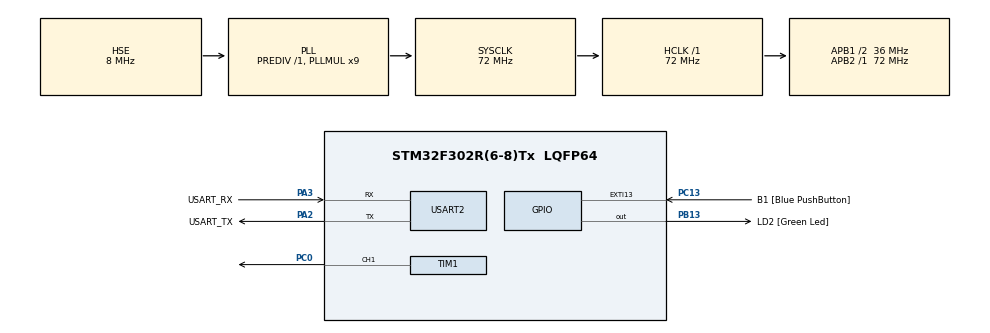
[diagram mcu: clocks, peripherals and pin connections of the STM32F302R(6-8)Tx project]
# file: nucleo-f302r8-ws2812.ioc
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Dma.Request0=TIM1_CH1
Dma.TIM1_CH1.0.Direction=DMA_MEMORY_TO_PERIPH
Dma.TIM1_CH1.0.Instance=DMA1_Channel2
Dma.TIM1_CH1.0.MemDataAlignment=DMA_MDATAALIGN_BYTE
Dma.TIM1_CH1.0.MemInc=DMA_MINC_ENABLE
Dma.TIM1_CH1.0.Mode=DMA_NORMAL
Dma.TIM1_CH1.0.PeriphDataAlignment=DMA_PDATAALIGN_HALFWORD
Dma.TIM1_CH1.0.PeriphInc=DMA_PINC_DISABLE
Dma.TIM1_CH1.0.Priority=DMA_PRIORITY_LOW
Mcu.Family=STM32F3
Mcu.Name=STM32F302R(6-8)Tx
Mcu.Package=LQFP64
NVIC.DMA1_Channel2_IRQn=true\:0\:0\:false\:false\:true\:false\:true\:true
NVIC.PriorityGroup=NVIC_PRIORITYGROUP_0
PA13.GPIO_Label=TMS
PA13.Mode=Serial_Wire
PA13.Signal=SYS_JTMS-SWDIO
PA14.GPIO_Label=TCK
PA14.Mode=Serial_Wire
PA14.Signal=SYS_JTCK-SWCLK
PA2.GPIO_Label=USART_TX
PA2.GPIO_Mode=GPIO_MODE_AF_PP
PA2.GPIO_PuPd=GPIO_NOPULL
PA2.GPIO_Speed=GPIO_SPEED_FREQ_LOW
PA2.Mode=Asynchronous
PA2.Signal=USART2_TX
PA3.GPIO_Label=USART_RX
PA3.GPIO_Mode=GPIO_MODE_AF_PP
PA3.GPIO_PuPd=GPIO_NOPULL
PA3.GPIO_Speed=GPIO_SPEED_FREQ_LOW
PA3.Mode=Asynchronous
PA3.Signal=USART2_RX
PB13.GPIO_Label=LD2 [Green Led]
PB13.Signal=GPIO_Output
PB3.GPIO_Label=SWO
PB3.Mode=Trace_Asynchronous_SW
PB3.Signal=SYS_JTDO-TRACESWO
PC0.GPIO_PuPd=GPIO_NOPULL
PC0.GPIO_Speed=GPIO_SPEED_FREQ_HIGH
PC0.Signal=S_TIM1_CH1
PC13.GPIO_Label=B1 [Blue PushButton]
PC13.GPIO_ModeDefaultEXTI=GPIO_MODE_IT_FALLING
PC13.Signal=GPXTI13
PC14\ -\ OSC32_IN.Mode=LSE-External-Oscillator
PC14\ -\ OSC32_IN.Signal=RCC_OSC32_IN
PC15\ -\ OSC32_OUT.Mode=LSE-External-Oscillator
PC15\ -\ OSC32_OUT.Signal=RCC_OSC32_OUT
PF0-OSC_IN.Mode=HSE-External-Clock-Source
PF0-OSC_IN.Signal=RCC_OSC_IN
PF1-OSC_OUT.Signal=RCC_OSC_OUT
ProjectManager.HeapSize=0x200
ProjectManager.StackSize=0x400
ProjectManager.TargetToolchain=Makefile
RCC.AHBFreq_Value=72000000
RCC.APB1CLKDivider=RCC_HCLK_DIV2
RCC.APB1Freq_Value=36000000
RCC.APB1TimFreq_Value=72000000
RCC.APB2Freq_Value=72000000
RCC.APB2TimFreq_Value=72000000
RCC.CortexFreq_Value=72000000
RCC.HCLKFreq_Value=72000000
RCC.HSE_VALUE=8000000
RCC.HSI_VALUE=8000000
RCC.PLLM=8
RCC.PLLMUL=RCC_PLL_MUL9
RCC.PLLN=336
RCC.PLLP=RCC_PLLP_DIV4
RCC.PLLQ=7
RCC.PLLSourceVirtual=RCC_PLLSOURCE_HSE
RCC.SYSCLKFreq_VALUE=72000000
RCC.SYSCLKSourceVirtual=RCC_SYSCLKSOURCE_PLLCLK
RCC.USBFreq_Value=72000000
SH.S_TIM1_CH1.0=TIM1_CH1,PWM Generation1 CH1
TIM1.AutoReloadPreload=TIM_AUTORELOAD_PRELOAD_ENABLE
TIM1.Channel-PWM\ Generation1\ CH1=TIM_CHANNEL_1
TIM1.Period=90-1
USART2.VirtualMode-Asynchronous=VM_ASYNC
VP_TIM1_VS_ClockSourceINT.Mode=Internal
board=NUCLEO-F302R8

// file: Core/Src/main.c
/* USER CODE BEGIN Header */
/**
  ******************************************************************************
  * @file           : main.c
  * @brief          : Main program body
  ******************************************************************************
  * @attention
  *
  * Copyright (c) 2024 STMicroelectronics.
  * All rights reserved.
  *
  * This software is licensed under terms that can be found in the LICENSE file
  * in the root directory of this software component.
  * If no LICENSE file comes with this software, it is provided AS-IS.
  *
  ******************************************************************************
  */
/* USER CODE END Header */
#include "main.h"

/* USER CODE BEGIN Includes */
#include "application.h"
/* USER CODE END Includes */

TIM_HandleTypeDef htim1;
DMA_HandleTypeDef hdma_tim1_ch1;

UART_HandleTypeDef huart2;

void SystemClock_Config(void);
static void MX_GPIO_Init(void);
static void MX_DMA_Init(void);
static void MX_USART2_UART_Init(void);
static void MX_TIM1_Init(void);
/* USER CODE BEGIN PFP */
void initialise_monitor_handles();
/* USER CODE END PFP */

int main(void)
{

  /* USER CODE BEGIN 1 */
  initialise_monitor_handles();
  /* USER CODE END 1 */

  /* MCU Configuration--------------------------------------------------------*/

  /* Reset of all peripherals, Initializes the Flash interface and the Systick. */
  HAL_Init();

  /* Configure the system clock */
  SystemClock_Config();

  /* Initialize all configured peripherals */
  MX_GPIO_Init();
  MX_DMA_Init();
  MX_USART2_UART_Init();
  MX_TIM1_Init();

  /* Infinite loop */
  /* USER CODE BEGIN WHILE */

  // Enable divide-by-zero trap
  SCB->CCR |= SCB_CCR_DIV_0_TRP_Msk;

  app_init();

  while (1)
  {
    /* USER CODE END WHILE */

    /* USER CODE BEGIN 3 */
    app_loop();
  }
  app_close();
  /* USER CODE END 3 */
}

void SystemClock_Config(void)
{
  RCC_OscInitTypeDef RCC_OscInitStruct = {0};
  RCC_ClkInitTypeDef RCC_ClkInitStruct = {0};
  RCC_PeriphCLKInitTypeDef PeriphClkInit = {0};

  /** Initializes the RCC Oscillators according to the specified parameters
  * in the RCC_OscInitTypeDef structure.
  */
  RCC_OscInitStruct.OscillatorType = RCC_OSCILLATORTYPE_HSE;
  RCC_OscInitStruct.HSEState = RCC_HSE_BYPASS;
  RCC_OscInitStruct.HSEPredivValue = RCC_HSE_PREDIV_DIV1;
  RCC_OscInitStruct.HSIState = RCC_HSI_ON;
  RCC_OscInitStruct.PLL.PLLState = RCC_PLL_ON;
  RCC_OscInitStruct.PLL.PLLSource = RCC_PLLSOURCE_HSE;
  RCC_OscInitStruct.PLL.PLLMUL = RCC_PLL_MUL9;
  if (HAL_RCC_OscConfig(&RCC_OscInitStruct) != HAL_OK)
  {
    Error_Handler();
  }

  /** Initializes the CPU, AHB and APB buses clocks
  */
  RCC_ClkInitStruct.ClockType = RCC_CLOCKTYPE_HCLK|RCC_CLOCKTYPE_SYSCLK
                              |RCC_CLOCKTYPE_PCLK1|RCC_CLOCKTYPE_PCLK2;
  RCC_ClkInitStruct.SYSCLKSource = RCC_SYSCLKSOURCE_PLLCLK;
  RCC_ClkInitStruct.AHBCLKDivider = RCC_SYSCLK_DIV1;
  RCC_ClkInitStruct.APB1CLKDivider = RCC_HCLK_DIV2;
  RCC_ClkInitStruct.APB2CLKDivider = RCC_HCLK_DIV1;

  if (HAL_RCC_ClockConfig(&RCC_ClkInitStruct, FLASH_LATENCY_2) != HAL_OK)
  {
    Error_Handler();
  }
  PeriphClkInit.PeriphClockSelection = RCC_PERIPHCLK_TIM1;
  PeriphClkInit.Tim1ClockSelection = RCC_TIM1CLK_HCLK;
  if (HAL_RCCEx_PeriphCLKConfig(&PeriphClkInit) != HAL_OK)
  {
    Error_Handler();
  }
}

static void MX_TIM1_Init(void)
{

  TIM_ClockConfigTypeDef sClockSourceConfig = {0};
  TIM_MasterConfigTypeDef sMasterConfig = {0};
  TIM_OC_InitTypeDef sConfigOC = {0};
  TIM_BreakDeadTimeConfigTypeDef sBreakDeadTimeConfig = {0};

  htim1.Instance = TIM1;
  htim1.Init.Prescaler = 0;
  htim1.Init.CounterMode = TIM_COUNTERMODE_UP;
  htim1.Init.Period = 90-1;
  htim1.Init.ClockDivision = TIM_CLOCKDIVISION_DIV1;
  htim1.Init.RepetitionCounter = 0;
  htim1.Init.AutoReloadPreload = TIM_AUTORELOAD_PRELOAD_ENABLE;
  if (HAL_TIM_Base_Init(&htim1) != HAL_OK)
  {
    Error_Handler();
  }
  sClockSourceConfig.ClockSource = TIM_CLOCKSOURCE_INTERNAL;
  if (HAL_TIM_ConfigClockSource(&htim1, &sClockSourceConfig) != HAL_OK)
  {
    Error_Handler();
  }
  if (HAL_TIM_PWM_Init(&htim1) != HAL_OK)
  {
    Error_Handler();
  }
  sMasterConfig.MasterOutputTrigger = TIM_TRGO_RESET;
  sMasterConfig.MasterOutputTrigger2 = TIM_TRGO2_RESET;
  sMasterConfig.MasterSlaveMode = TIM_MASTERSLAVEMODE_DISABLE;
  if (HAL_TIMEx_MasterConfigSynchronization(&htim1, &sMasterConfig) != HAL_OK)
  {
    Error_Handler();
  }
  sConfigOC.OCMode = TIM_OCMODE_PWM1;
  sConfigOC.Pulse = 0;
  sConfigOC.OCPolarity = TIM_OCPOLARITY_HIGH;
  sConfigOC.OCNPolarity = TIM_OCNPOLARITY_HIGH;
  sConfigOC.OCFastMode = TIM_OCFAST_DISABLE;
  sConfigOC.OCIdleState = TIM_OCIDLESTATE_RESET;
  sConfigOC.OCNIdleState = TIM_OCNIDLESTATE_RESET;
  if (HAL_TIM_PWM_ConfigChannel(&htim1, &sConfigOC, TIM_CHANNEL_1) != HAL_OK)
  {
    Error_Handler();
  }
  sBreakDeadTimeConfig.OffStateRunMode = TIM_OSSR_DISABLE;
  sBreakDeadTimeConfig.OffStateIDLEMode = TIM_OSSI_DISABLE;
  sBreakDeadTimeConfig.LockLevel = TIM_LOCKLEVEL_OFF;
  sBreakDeadTimeConfig.DeadTime = 0;
  sBreakDeadTimeConfig.BreakState = TIM_BREAK_DISABLE;
  sBreakDeadTimeConfig.BreakPolarity = TIM_BREAKPOLARITY_HIGH;
  sBreakDeadTimeConfig.BreakFilter = 0;
  sBreakDeadTimeConfig.Break2State = TIM_BREAK2_DISABLE;
  sBreakDeadTimeConfig.Break2Polarity = TIM_BREAK2POLARITY_HIGH;
  sBreakDeadTimeConfig.Break2Filter = 0;
  sBreakDeadTimeConfig.AutomaticOutput = TIM_AUTOMATICOUTPUT_DISABLE;
  if (HAL_TIMEx_ConfigBreakDeadTime(&htim1, &sBreakDeadTimeConfig) != HAL_OK)
  {
    Error_Handler();
  }
  HAL_TIM_MspPostInit(&htim1);

}

static void MX_USART2_UART_Init(void)
{

  huart2.Instance = USART2;
  huart2.Init.BaudRate = 38400;
  huart2.Init.WordLength = UART_WORDLENGTH_8B;
  huart2.Init.StopBits = UART_STOPBITS_1;
  huart2.Init.Parity = UART_PARITY_NONE;
  huart2.Init.Mode = UART_MODE_TX_RX;
  huart2.Init.HwFlowCtl = UART_HWCONTROL_NONE;
  huart2.Init.OverSampling = UART_OVERSAMPLING_16;
  huart2.Init.OneBitSampling = UART_ONE_BIT_SAMPLE_DISABLE;
  huart2.AdvancedInit.AdvFeatureInit = UART_ADVFEATURE_NO_INIT;
  if (HAL_UART_Init(&huart2) != HAL_OK)
  {
    Error_Handler();
  }

}

static void MX_DMA_Init(void)
{

  /* DMA controller clock enable */
  __HAL_RCC_DMA1_CLK_ENABLE();

  /* DMA interrupt init */
  /* DMA1_Channel2_IRQn interrupt configuration */
  HAL_NVIC_SetPriority(DMA1_Channel2_IRQn, 0, 0);
  HAL_NVIC_EnableIRQ(DMA1_Channel2_IRQn);

}

static void MX_GPIO_Init(void)
{
  GPIO_InitTypeDef GPIO_InitStruct = {0};

  /* GPIO Ports Clock Enable */
  __HAL_RCC_GPIOC_CLK_ENABLE();
  __HAL_RCC_GPIOF_CLK_ENABLE();
  __HAL_RCC_GPIOA_CLK_ENABLE();
  __HAL_RCC_GPIOB_CLK_ENABLE();

  /*Configure GPIO pin Output Level */
  HAL_GPIO_WritePin(LD2_GPIO_Port, LD2_Pin, GPIO_PIN_RESET);

  /*Configure GPIO pin : B1_Pin */
  GPIO_InitStruct.Pin = B1_Pin;
  GPIO_InitStruct.Mode = GPIO_MODE_IT_FALLING;
  GPIO_InitStruct.Pull = GPIO_NOPULL;
  HAL_GPIO_Init(B1_GPIO_Port, &GPIO_InitStruct);

  /*Configure GPIO pin : LD2_Pin */
  GPIO_InitStruct.Pin = LD2_Pin;
  GPIO_InitStruct.Mode = GPIO_MODE_OUTPUT_PP;
  GPIO_InitStruct.Pull = GPIO_NOPULL;
  GPIO_InitStruct.Speed = GPIO_SPEED_FREQ_LOW;
  HAL_GPIO_Init(LD2_GPIO_Port, &GPIO_InitStruct);

}

void Error_Handler(void)
{
  __disable_irq();
  while (1)
  {
  }
}
